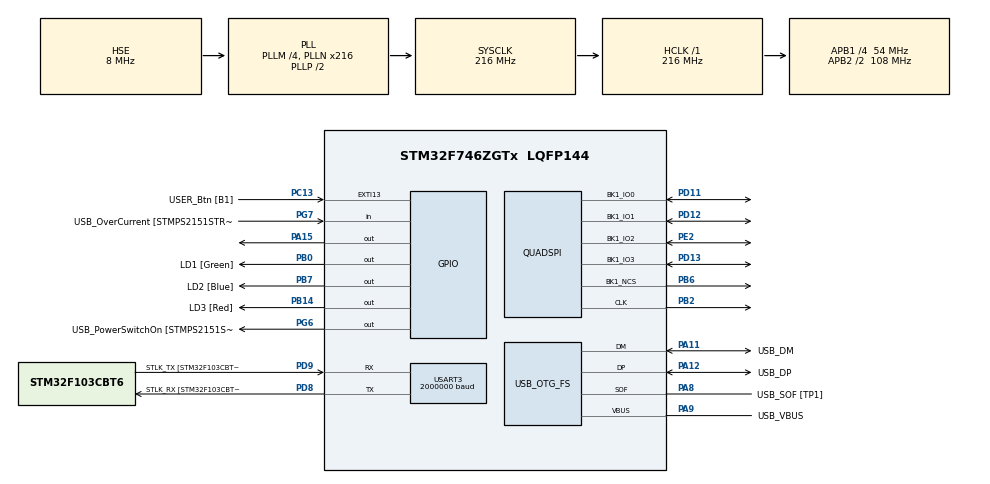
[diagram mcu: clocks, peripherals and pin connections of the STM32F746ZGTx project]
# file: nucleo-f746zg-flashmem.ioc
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FREERTOS.Queues01=uartQueue,64,64,1,Dynamic,NULL,NULL;cmdParamQueue,8,uint32_t,0,Dynamic,NULL,NULL
FREERTOS.Tasks01=myTask01,40,256,startTask01,Default,NULL,Dynamic,NULL,NULL
FREERTOS.configTOTAL_HEAP_SIZE=65536
FREERTOS.configUSE_NEWLIB_REENTRANT=1
Mcu.Family=STM32F7
Mcu.Name=STM32F746ZGTx
Mcu.Package=LQFP144
NVIC.PriorityGroup=NVIC_PRIORITYGROUP_4
NVIC.TIM6_DAC_IRQn=true\:15\:0\:false\:false\:true\:false\:false\:true\:true
NVIC.TimeBase=TIM6_DAC_IRQn
NVIC.TimeBaseIP=TIM6
NVIC.USART3_IRQn=true\:5\:0\:true\:false\:true\:true\:true\:true\:true
PA1.GPIO_Label=RMII_REF_CLK [LAN8742A-CZ-TR_REFCLK0]
PA1.Signal=ETH_REF_CLK
PA10.GPIO_Label=USB_ID
PA10.Signal=USB_OTG_FS_ID
PA11.GPIO_Label=USB_DM
PA11.Mode=Device_Only
PA11.Signal=USB_OTG_FS_DM
PA12.GPIO_Label=USB_DP
PA12.Mode=Device_Only
PA12.Signal=USB_OTG_FS_DP
PA13.GPIO_Label=TMS
PA13.Mode=Serial_Wire
PA13.Signal=SYS_JTMS-SWDIO
PA14.GPIO_Label=TCK
PA14.Mode=Serial_Wire
PA14.Signal=SYS_JTCK-SWCLK
PA15.Signal=GPIO_Output
PA2.GPIO_Label=RMII_MDIO [LAN8742A-CZ-TR_MDIO]
PA2.Signal=ETH_MDIO
PA7.Signal=SPI1_MOSI
PA8.GPIO_Label=USB_SOF [TP1]
PA8.Mode=Activate_SOF_FS
PA8.Signal=USB_OTG_FS_SOF
PA9.GPIO_Label=USB_VBUS
PA9.Mode=Activate_VBUS
PA9.Signal=USB_OTG_FS_VBUS
PB0.GPIO_Label=LD1 [Green]
PB0.Signal=GPIO_Output
PB13.GPIO_Label=RMII_TXD1 [LAN8742A-CZ-TR_TXD1]
PB13.Signal=ETH_TXD1
PB14.GPIO_Label=LD3 [Red]
PB14.Signal=GPIO_Output
PB2.GPIO_Speed=GPIO_SPEED_FREQ_VERY_HIGH
PB2.Mode=Single Bank 1
PB2.Signal=QUADSPI_CLK
PB3.GPIO_Label=SW0
PB3.Signal=SYS_JTDO-SWO
PB6.GPIO_Speed=GPIO_SPEED_FREQ_VERY_HIGH
PB6.Mode=Single Bank 1
PB6.Signal=QUADSPI_BK1_NCS
PB7.GPIO_Label=LD2 [Blue]
PB7.Signal=GPIO_Output
PB8.Signal=I2C1_SCL
PB9.Signal=I2C1_SDA
PC13.GPIO_Label=USER_Btn [B1]
PC13.Signal=GPXTI13
PC14/OSC32_IN.Mode=LSE-External-Oscillator
PC14/OSC32_IN.Signal=RCC_OSC32_IN
PC15/OSC32_OUT.Mode=LSE-External-Oscillator
PC15/OSC32_OUT.Signal=RCC_OSC32_OUT
PC4.GPIO_Label=RMII_RXD0 [LAN8742A-CZ-TR_RXD0]
PC4.Signal=ETH_RXD0
PC5.GPIO_Label=RMII_RXD1 [LAN8742A-CZ-TR_RXD1]
PC5.Signal=ETH_RXD1
PD11.GPIO_Speed=GPIO_SPEED_FREQ_VERY_HIGH
PD11.Mode=Single Bank 1
PD11.Signal=QUADSPI_BK1_IO0
PD12.GPIO_Speed=GPIO_SPEED_FREQ_VERY_HIGH
PD12.Mode=Single Bank 1
PD12.Signal=QUADSPI_BK1_IO1
PD13.GPIO_Speed=GPIO_SPEED_FREQ_VERY_HIGH
PD13.Mode=Single Bank 1
PD13.Signal=QUADSPI_BK1_IO3
PD8.GPIO_Label=STLK_RX [STM32F103CBT6_PA3]
PD8.GPIO_PuPd=GPIO_PULLUP
PD8.Mode=Asynchronous
PD8.Signal=USART3_TX
PD9.GPIO_Label=STLK_TX [STM32F103CBT6_PA2]
PD9.GPIO_PuPd=GPIO_PULLUP
PD9.Mode=Asynchronous
PD9.Signal=USART3_RX
PE2.GPIO_Speed=GPIO_SPEED_FREQ_VERY_HIGH
PE2.Mode=Single Bank 1
PE2.Signal=QUADSPI_BK1_IO2
PG11.GPIO_Label=RMII_TX_EN [LAN8742A-CZ-TR_TXEN]
PG11.Signal=ETH_TX_EN
PG13.GPIO_Label=RMII_TXD0 [LAN8742A-CZ-TR_TXD0]
PG13.Signal=ETH_TXD0
PG6.GPIO_Label=USB_PowerSwitchOn [STMPS2151STR_EN]
PG6.Signal=GPIO_Output
PG7.GPIO_Label=USB_OverCurrent [STMPS2151STR_FAULT]
PG7.Signal=GPIO_Input
PH0/OSC_IN.GPIO_Label=MCO [STM32F103CBT6_PA8]
PH0/OSC_IN.Mode=HSE-External-Clock-Source
PH0/OSC_IN.Signal=RCC_OSC_IN
PH1/OSC_OUT.Mode=HSE-External-Clock-Source
PH1/OSC_OUT.Signal=RCC_OSC_OUT
ProjectManager.HeapSize=0x200
ProjectManager.StackSize=0x400
ProjectManager.TargetToolchain=STM32CubeIDE
QUADSPI.ChipSelectHighTime=QSPI_CS_HIGH_TIME_1_CYCLE
QUADSPI.ClockPrescaler=3
QUADSPI.DeviceType=SPI_DEVICE_FLASH
QUADSPI.FifoThreshold=1
QUADSPI.FlashSize=28
QUADSPI.SampleShifting=QSPI_SAMPLE_SHIFTING_HALFCYCLE
RCC.48MHZClocksFreq_Value=24000000
RCC.AHBFreq_Value=216000000
RCC.APB1CLKDivider=RCC_HCLK_DIV4
RCC.APB1Freq_Value=54000000
RCC.APB1TimFreq_Value=108000000
RCC.APB2CLKDivider=RCC_HCLK_DIV2
RCC.APB2Freq_Value=108000000
RCC.APB2TimFreq_Value=216000000
RCC.CortexFreq_Value=216000000
RCC.HCLKFreq_Value=216000000
RCC.HSE_VALUE=8000000
RCC.HSI_VALUE=16000000
RCC.PLLM=4
RCC.PLLMUL=RCC_PLL_MUL9
RCC.PLLN=216
RCC.PLLQ=9
RCC.PRESCALERUSB=RCC_USBCLKSOURCE_PLL_DIV1_5
RCC.SYSCLKFreq_VALUE=216000000
RCC.SYSCLKSource=RCC_SYSCLKSOURCE_PLLCLK
RCC.SYSCLKSourceVirtual=RCC_SYSCLKSOURCE_PLLCLK
RCC.USBFreq_Value=48000000
RCC.VCOOutputFreq_Value=432000000
USART3.BaudRate=2000000
USART3.VirtualMode-Asynchronous=VM_ASYNC
USB_OTG_FS.VirtualMode=Device_Only
VP_FREERTOS_VS_CMSIS_V2.Mode=CMSIS_V2
VP_SYS_VS_tim6.Mode=TIM6
board=NUCLEO-F746ZG

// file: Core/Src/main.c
/* USER CODE BEGIN Header */
/**
 ******************************************************************************
 * @file           : main.c
 * @brief          : Main program body
 ******************************************************************************
 * @attention
 *
 * Copyright (c) 2024 STMicroelectronics.
 * All rights reserved.
 *
 * This software is licensed under terms that can be found in the LICENSE file
 * in the root directory of this software component.
 * If no LICENSE file comes with this software, it is provided AS-IS.
 *
 ******************************************************************************
 */
/* USER CODE END Header */
#include "main.h"
#include "cmsis_os.h"

/* USER CODE BEGIN Includes */
#include <W25N04KV.h>
/* USER CODE END Includes */

QSPI_HandleTypeDef hqspi;

UART_HandleTypeDef huart3;

PCD_HandleTypeDef hpcd_USB_OTG_FS;

/* Definitions for myTask01 */
osThreadId_t myTask01Handle;
const osThreadAttr_t myTask01_attributes = {
    .name = "myTask01",
    .stack_size = 256 * 4,
    .priority = (osPriority_t)osPriorityHigh,
};
/* Definitions for uartQueue */
osMessageQueueId_t uartQueueHandle;
const osMessageQueueAttr_t uartQueue_attributes = {.name = "uartQueue"};
/* Definitions for cmdParamQueue */
osMessageQueueId_t cmdParamQueueHandle;
const osMessageQueueAttr_t cmdParamQueue_attributes = {.name = "cmdParamQueue"};

void SystemClock_Config(void);
static void MX_GPIO_Init(void);
static void MX_USART3_UART_Init(void);
static void MX_USB_OTG_FS_PCD_Init(void);
static void MX_QUADSPI_Init(void);
void startTask01(void *argument);

/* USER CODE BEGIN PFP */
#define PUTCHAR_PROTOTYPE int __io_putchar(int ch)
/* USER CODE END PFP */

int main(void)
{

    /* MCU Configuration--------------------------------------------------------*/

    /* Reset of all peripherals, Initializes the Flash interface and the Systick. */
    HAL_Init();

    /* USER CODE BEGIN Init */
    __HAL_DBGMCU_FREEZE_TIM6();       //! Freeze TIM6 during debug halt
    setvbuf(stdout, NULL, _IONBF, 0); //! Disables buffering for stdout
    /* USER CODE END Init */

    /* Configure the system clock */
    SystemClock_Config();

    /* Initialize all configured peripherals */
    MX_GPIO_Init();
    MX_USART3_UART_Init();
    MX_USB_OTG_FS_PCD_Init();
    MX_QUADSPI_Init();

    /* Init scheduler */
    osKernelInitialize();

    /* Create the queue(s) */
    /* creation of uartQueue */
    uartQueueHandle = osMessageQueueNew(64, 64, &uartQueue_attributes);

    /* creation of cmdParamQueue */
    cmdParamQueueHandle = osMessageQueueNew(8, sizeof(uint32_t), &cmdParamQueue_attributes);

    /* Create the thread(s) */
    /* creation of myTask01 */
    myTask01Handle = osThreadNew(startTask01, NULL, &myTask01_attributes);

    /* USER CODE BEGIN RTOS_THREADS */
    xTaskCreate(W25N04KV_InitCLI, "CLI", 2048 * 4, NULL, osPriorityNormal, NULL); // Create the CLI task
    /* add threads, ... */
    /* USER CODE END RTOS_THREADS */

    /* Start scheduler */
    osKernelStart();

    /* We should never get here as control is now taken by the scheduler */

    /* Infinite loop */
    while (1)
    {

    }
}

void SystemClock_Config(void)
{
    RCC_OscInitTypeDef RCC_OscInitStruct = {0};
    RCC_ClkInitTypeDef RCC_ClkInitStruct = {0};

    /** Configure LSE Drive Capability
     */
    HAL_PWR_EnableBkUpAccess();

    /** Configure the main internal regulator output voltage
     */
    __HAL_RCC_PWR_CLK_ENABLE();
    __HAL_PWR_VOLTAGESCALING_CONFIG(PWR_REGULATOR_VOLTAGE_SCALE1);

    /** Initializes the RCC Oscillators according to the specified parameters
     * in the RCC_OscInitTypeDef structure.
     */
    RCC_OscInitStruct.OscillatorType = RCC_OSCILLATORTYPE_HSE;
    RCC_OscInitStruct.HSEState = RCC_HSE_BYPASS;
    RCC_OscInitStruct.PLL.PLLState = RCC_PLL_ON;
    RCC_OscInitStruct.PLL.PLLSource = RCC_PLLSOURCE_HSE;
    RCC_OscInitStruct.PLL.PLLM = 4;
    RCC_OscInitStruct.PLL.PLLN = 216;
    RCC_OscInitStruct.PLL.PLLP = RCC_PLLP_DIV2;
    RCC_OscInitStruct.PLL.PLLQ = 9;
    if (HAL_RCC_OscConfig(&RCC_OscInitStruct) != HAL_OK)
    {
        Error_Handler();
    }

    /** Activate the Over-Drive mode
     */
    if (HAL_PWREx_EnableOverDrive() != HAL_OK)
    {
        Error_Handler();
    }

    /** Initializes the CPU, AHB and APB buses clocks
     */
    RCC_ClkInitStruct.ClockType = RCC_CLOCKTYPE_HCLK | RCC_CLOCKTYPE_SYSCLK | RCC_CLOCKTYPE_PCLK1 | RCC_CLOCKTYPE_PCLK2;
    RCC_ClkInitStruct.SYSCLKSource = RCC_SYSCLKSOURCE_PLLCLK;
    RCC_ClkInitStruct.AHBCLKDivider = RCC_SYSCLK_DIV1;
    RCC_ClkInitStruct.APB1CLKDivider = RCC_HCLK_DIV4;
    RCC_ClkInitStruct.APB2CLKDivider = RCC_HCLK_DIV2;

    if (HAL_RCC_ClockConfig(&RCC_ClkInitStruct, FLASH_LATENCY_7) != HAL_OK)
    {
        Error_Handler();
    }
}

static void MX_QUADSPI_Init(void)
{

    /* QUADSPI parameter configuration*/
    hqspi.Instance = QUADSPI;
    hqspi.Init.ClockPrescaler = 3;
    hqspi.Init.FifoThreshold = 1;
    hqspi.Init.SampleShifting = QSPI_SAMPLE_SHIFTING_HALFCYCLE;
    hqspi.Init.FlashSize = 28;
    hqspi.Init.ChipSelectHighTime = QSPI_CS_HIGH_TIME_1_CYCLE;
    hqspi.Init.ClockMode = QSPI_CLOCK_MODE_0;
    hqspi.Init.FlashID = QSPI_FLASH_ID_1;
    hqspi.Init.DualFlash = QSPI_DUALFLASH_DISABLE;
    if (HAL_QSPI_Init(&hqspi) != HAL_OK)
    {
        Error_Handler();
    }
}

static void MX_USART3_UART_Init(void)
{

    huart3.Instance = USART3;
    huart3.Init.BaudRate = 2000000;
    huart3.Init.WordLength = UART_WORDLENGTH_8B;
    huart3.Init.StopBits = UART_STOPBITS_1;
    huart3.Init.Parity = UART_PARITY_NONE;
    huart3.Init.Mode = UART_MODE_TX_RX;
    huart3.Init.HwFlowCtl = UART_HWCONTROL_NONE;
    huart3.Init.OverSampling = UART_OVERSAMPLING_16;
    huart3.Init.OneBitSampling = UART_ONE_BIT_SAMPLE_DISABLE;
    huart3.AdvancedInit.AdvFeatureInit = UART_ADVFEATURE_NO_INIT;
    if (HAL_UART_Init(&huart3) != HAL_OK)
    {
        Error_Handler();
    }
}

static void MX_USB_OTG_FS_PCD_Init(void)
{

    hpcd_USB_OTG_FS.Instance = USB_OTG_FS;
    hpcd_USB_OTG_FS.Init.dev_endpoints = 6;
    hpcd_USB_OTG_FS.Init.speed = PCD_SPEED_FULL;
    hpcd_USB_OTG_FS.Init.dma_enable = DISABLE;
    hpcd_USB_OTG_FS.Init.phy_itface = PCD_PHY_EMBEDDED;
    hpcd_USB_OTG_FS.Init.Sof_enable = ENABLE;
    hpcd_USB_OTG_FS.Init.low_power_enable = DISABLE;
    hpcd_USB_OTG_FS.Init.lpm_enable = DISABLE;
    hpcd_USB_OTG_FS.Init.vbus_sensing_enable = ENABLE;
    hpcd_USB_OTG_FS.Init.use_dedicated_ep1 = DISABLE;
    if (HAL_PCD_Init(&hpcd_USB_OTG_FS) != HAL_OK)
    {
        Error_Handler();
    }
}

static void MX_GPIO_Init(void)
{
    GPIO_InitTypeDef GPIO_InitStruct = {0};

    /* GPIO Ports Clock Enable */
    __HAL_RCC_GPIOE_CLK_ENABLE();
    __HAL_RCC_GPIOC_CLK_ENABLE();
    __HAL_RCC_GPIOH_CLK_ENABLE();
    __HAL_RCC_GPIOA_CLK_ENABLE();
    __HAL_RCC_GPIOB_CLK_ENABLE();
    __HAL_RCC_GPIOD_CLK_ENABLE();
    __HAL_RCC_GPIOG_CLK_ENABLE();

    /*Configure GPIO pin Output Level */
    HAL_GPIO_WritePin(GPIOB, LD1_Pin | LD3_Pin | LD2_Pin, GPIO_PIN_RESET);

    /*Configure GPIO pin Output Level */
    HAL_GPIO_WritePin(USB_PowerSwitchOn_GPIO_Port, USB_PowerSwitchOn_Pin, GPIO_PIN_RESET);

    /*Configure GPIO pin Output Level */
    HAL_GPIO_WritePin(GPIOA, GPIO_PIN_15, GPIO_PIN_RESET);

    /*Configure GPIO pin : USER_Btn_Pin */
    GPIO_InitStruct.Pin = USER_Btn_Pin;
    GPIO_InitStruct.Mode = GPIO_MODE_IT_RISING;
    GPIO_InitStruct.Pull = GPIO_NOPULL;
    HAL_GPIO_Init(USER_Btn_GPIO_Port, &GPIO_InitStruct);

    /*Configure GPIO pins : RMII_REF_CLK_Pin RMII_MDIO_Pin */
    GPIO_InitStruct.Pin = RMII_REF_CLK_Pin | RMII_MDIO_Pin;
    GPIO_InitStruct.Mode = GPIO_MODE_AF_PP;
    GPIO_InitStruct.Pull = GPIO_NOPULL;
    GPIO_InitStruct.Speed = GPIO_SPEED_FREQ_VERY_HIGH;
    GPIO_InitStruct.Alternate = GPIO_AF11_ETH;
    HAL_GPIO_Init(GPIOA, &GPIO_InitStruct);

    /*Configure GPIO pin : PA7 */
    GPIO_InitStruct.Pin = GPIO_PIN_7;
    GPIO_InitStruct.Mode = GPIO_MODE_AF_PP;
    GPIO_InitStruct.Pull = GPIO_NOPULL;
    GPIO_InitStruct.Speed = GPIO_SPEED_FREQ_VERY_HIGH;
    GPIO_InitStruct.Alternate = GPIO_AF5_SPI1;
    HAL_GPIO_Init(GPIOA, &GPIO_InitStruct);

    /*Configure GPIO pins : RMII_RXD0_Pin RMII_RXD1_Pin */
    GPIO_InitStruct.Pin = RMII_RXD0_Pin | RMII_RXD1_Pin;
    GPIO_InitStruct.Mode = GPIO_MODE_AF_PP;
    GPIO_InitStruct.Pull = GPIO_NOPULL;
    GPIO_InitStruct.Speed = GPIO_SPEED_FREQ_VERY_HIGH;
    GPIO_InitStruct.Alternate = GPIO_AF11_ETH;
    HAL_GPIO_Init(GPIOC, &GPIO_InitStruct);

    /*Configure GPIO pins : LD1_Pin LD3_Pin LD2_Pin */
    GPIO_InitStruct.Pin = LD1_Pin | LD3_Pin | LD2_Pin;
    GPIO_InitStruct.Mode = GPIO_MODE_OUTPUT_PP;
    GPIO_InitStruct.Pull = GPIO_NOPULL;
    GPIO_InitStruct.Speed = GPIO_SPEED_FREQ_LOW;
    HAL_GPIO_Init(GPIOB, &GPIO_InitStruct);

    /*Configure GPIO pin : RMII_TXD1_Pin */
    GPIO_InitStruct.Pin = RMII_TXD1_Pin;
    GPIO_InitStruct.Mode = GPIO_MODE_AF_PP;
    GPIO_InitStruct.Pull = GPIO_NOPULL;
    GPIO_InitStruct.Speed = GPIO_SPEED_FREQ_VERY_HIGH;
    GPIO_InitStruct.Alternate = GPIO_AF11_ETH;
    HAL_GPIO_Init(RMII_TXD1_GPIO_Port, &GPIO_InitStruct);

    /*Configure GPIO pin : USB_PowerSwitchOn_Pin */
    GPIO_InitStruct.Pin = USB_PowerSwitchOn_Pin;
    GPIO_InitStruct.Mode = GPIO_MODE_OUTPUT_PP;
    GPIO_InitStruct.Pull = GPIO_NOPULL;
    GPIO_InitStruct.Speed = GPIO_SPEED_FREQ_LOW;
    HAL_GPIO_Init(USB_PowerSwitchOn_GPIO_Port, &GPIO_InitStruct);

    /*Configure GPIO pin : USB_OverCurrent_Pin */
    GPIO_InitStruct.Pin = USB_OverCurrent_Pin;
    GPIO_InitStruct.Mode = GPIO_MODE_INPUT;
    GPIO_InitStruct.Pull = GPIO_NOPULL;
    HAL_GPIO_Init(USB_OverCurrent_GPIO_Port, &GPIO_InitStruct);

    /*Configure GPIO pin : PA15 */
    GPIO_InitStruct.Pin = GPIO_PIN_15;
    GPIO_InitStruct.Mode = GPIO_MODE_OUTPUT_PP;
    GPIO_InitStruct.Pull = GPIO_NOPULL;
    GPIO_InitStruct.Speed = GPIO_SPEED_FREQ_LOW;
    HAL_GPIO_Init(GPIOA, &GPIO_InitStruct);

    /*Configure GPIO pins : RMII_TX_EN_Pin RMII_TXD0_Pin */
    GPIO_InitStruct.Pin = RMII_TX_EN_Pin | RMII_TXD0_Pin;
    GPIO_InitStruct.Mode = GPIO_MODE_AF_PP;
    GPIO_InitStruct.Pull = GPIO_NOPULL;
    GPIO_InitStruct.Speed = GPIO_SPEED_FREQ_VERY_HIGH;
    GPIO_InitStruct.Alternate = GPIO_AF11_ETH;
    HAL_GPIO_Init(GPIOG, &GPIO_InitStruct);

    /*Configure GPIO pins : PB8 PB9 */
    GPIO_InitStruct.Pin = GPIO_PIN_8 | GPIO_PIN_9;
    GPIO_InitStruct.Mode = GPIO_MODE_AF_OD;
    GPIO_InitStruct.Pull = GPIO_NOPULL;
    GPIO_InitStruct.Speed = GPIO_SPEED_FREQ_VERY_HIGH;
    GPIO_InitStruct.Alternate = GPIO_AF4_I2C1;
    HAL_GPIO_Init(GPIOB, &GPIO_InitStruct);

}

/* USER CODE BEGIN 4 */
/**
 * @brief  Retargets the C library printf function to the USART.
 *   None
 * @retval None
 */
PUTCHAR_PROTOTYPE
{
    /* Place your implementation of fputc here */
    /* e.g. write a character to the USART1 and Loop until the end of transmission */
    HAL_UART_Transmit(&huart3, (uint8_t *)&ch, 1, 0xFFFF);

    return ch;
}
/* USER CODE END 4 */

void startTask01(void *argument)
{
    /* USER CODE BEGIN 5 */
    vTaskSuspend(NULL); // Suspend the current task indefinitely

    /* Infinite loop */
    for (;;)
    {
        // We should never reach here
    }
    /* USER CODE END 5 */
}

void HAL_TIM_PeriodElapsedCallback(TIM_HandleTypeDef *htim)
{
    if (htim->Instance == TIM6)
    {
        HAL_IncTick();
    }
}

void Error_Handler(void)
{
    __disable_irq();
    while (1)
    {
    }
}
